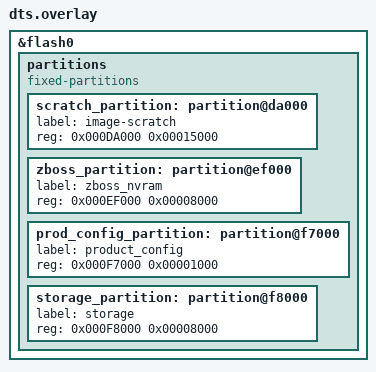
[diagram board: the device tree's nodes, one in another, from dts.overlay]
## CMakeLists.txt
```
#
# Copyright (c) 2020 Nordic Semiconductor ASA
#
# SPDX-License-Identifier: LicenseRef-BSD-5-Clause-Nordic
#

cmake_minimum_required(VERSION 3.13.1)

find_package(Zephyr REQUIRED HINTS $ENV{ZEPHYR_BASE})

project("Zigbee light bulb")

# NORDIC SDK APP START
target_sources(app PRIVATE
  src/main.c
  src/thran.c
)
# NORDIC SDK APP END
```

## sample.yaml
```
sample:
  name: Zigbee Light control
  description: Zigbee Light control - light bulb sample
tests:
  samples.zigbee.light_bulb:
    platform_whitelist: nrf52840dk_nrf52840
    harness: zigbee
    tags: zigbee
  zigbee.light_bulb:
    build_only: true
    build_on_all: true
    platform_whitelist: nrf52840dk_nrf52840 nrf52833dk_nrf52833
    tags: ci_build
```

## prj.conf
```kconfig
#
# Copyright (c) 2020 Nordic Semiconductor ASA
#
# SPDX-License-Identifier: LicenseRef-Nordic-5-Clause
#

CONFIG_NCS_SAMPLES_DEFAULTS=y

CONFIG_UART_INTERRUPT_DRIVEN=y
CONFIG_SERIAL=y
CONFIG_GPIO=y
CONFIG_PWM=y

# Make sure printk is not printing to the UART console
CONFIG_CONSOLE=y
CONFIG_UART_CONSOLE=y

CONFIG_LOG=y

CONFIG_HEAP_MEM_POOL_SIZE=2048
CONFIG_MAIN_THREAD_PRIORITY=7

CONFIG_ZIGBEE=y
CONFIG_ZIGBEE_APP_UTILS=y
CONFIG_ZIGBEE_ROLE_ROUTER=y

# Enable DK LED and Buttons library
CONFIG_DK_LIBRARY=y

# This example requires more workqueue stack
CONFIG_SYSTEM_WORKQUEUE_STACK_SIZE=2048

# Enable nRF ECB driver
CONFIG_CRYPTO=y
CONFIG_CRYPTO_NRF_ECB=y

# Cryptocell is not supported through CSPRNG driver API: NCSDK-4813
CONFIG_ENTROPY_CC3XX=n

#Networking
CONFIG_NET_IPV6_MLD=n
CONFIG_NET_IPV6_NBR_CACHE=n
CONFIG_NET_IPV6_RA_RDNSS=n
CONFIG_NET_IP_ADDR_CHECK=n
CONFIG_NET_UDP=n

#settings storage
CONFIG_NVS=y
CONFIG_SETTINGS=y

#development version of ZBOSS lib
CONFIG_ZIGBEE_LIBRARY_DEVELOPMENT=y
```

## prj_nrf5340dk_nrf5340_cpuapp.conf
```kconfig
#
# Copyright (c) 2020 Nordic Semiconductor ASA
#
# SPDX-License-Identifier: LicenseRef-Nordic-5-Clause
#

CONFIG_NCS_SAMPLES_DEFAULTS=y

CONFIG_UART_INTERRUPT_DRIVEN=y
CONFIG_SERIAL=y
CONFIG_GPIO=y
CONFIG_PWM=y

# Make sure printk is not printing to the UART console
CONFIG_CONSOLE=y
CONFIG_UART_CONSOLE=y

CONFIG_LOG=y

CONFIG_HEAP_MEM_POOL_SIZE=2048
CONFIG_MAIN_THREAD_PRIORITY=7
CONFIG_MAIN_STACK_SIZE=2048

CONFIG_ZIGBEE=y
CONFIG_ZIGBEE_APP_UTILS=y
CONFIG_ZIGBEE_ROLE_ROUTER=y

# Enable DK LED and Buttons library
CONFIG_DK_LIBRARY=y

# This example requires more workqueue stack
CONFIG_SYSTEM_WORKQUEUE_STACK_SIZE=2048

# Use software cryptography on nRF5340
CONFIG_TINYCRYPT=y
CONFIG_CTR_DRBG_CSPRNG_GENERATOR=y
CONFIG_ZIGBEE_USE_SOFTWARE_AES=y

#Networking
CONFIG_MPSL=n
CONFIG_NET_IPV6_MLD=n
CONFIG_NET_IPV6_NBR_CACHE=n
CONFIG_NET_IPV6_RA_RDNSS=n
CONFIG_NET_IP_ADDR_CHECK=n
CONFIG_NET_UDP=n

#settings storage
CONFIG_NVS=y
CONFIG_SETTINGS=y

#development version of ZBOSS lib
CONFIG_ZIGBEE_LIBRARY_DEVELOPMENT=y
```

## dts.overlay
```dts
/* Copyright (c) 2019 Nordic Semiconductor ASA
 *
 * SPDX-License-Identifier: Apache-2.0
 */
 
 /delete-node/ &scratch_partition;
 /delete-node/ &storage_partition;
 
 &flash0 {
	partitions {
		compatible = "fixed-partitions";
		#address-cells = <1>;
		#size-cells = <1>;

		scratch_partition: partition@da000 {
			label = "image-scratch";
			reg = <0x000DA000 0x00015000>;
		};
		zboss_partition: partition@ef000 {
			label = "zboss_nvram";
			reg = <0x000EF000 0x00008000>;
		};
		prod_config_partition: partition@f7000 {
			label = "product_config";
			reg = <0x000F7000 0x00001000>;
		};
		storage_partition: partition@f8000 {
			label = "storage";
			reg = <0x000F8000 0x00008000>;
		};
	};
};
```

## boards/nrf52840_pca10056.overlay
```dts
/* Copyright (c) 2019 Nordic Semiconductor ASA
 *
 * SPDX-License-Identifier: Apache-2.0
 */

/ {
    pwmleds {
		pwm_led3: pwm_led_3 {
			pwms = <&pwm0 16>;
		};
	};
};

&pwm0 {
	ch1-pin = <16>;
	ch1-inverted;
};
```

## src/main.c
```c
/*
 * Copyright (c) 2020 Nordic Semiconductor ASA
 *
 * SPDX-License-Identifier: LicenseRef-Nordic-5-Clause
 */

/** @file
 *
 * @brief Simple Zigbee light bulb implementation.
 */

#include <zephyr/types.h>
#include <zephyr.h>
#include <device.h>
#include <soc.h>
#include <drivers/pwm.h>
#include <logging/log.h>
#include <dk_buttons_and_leds.h>
#include <settings/settings.h>

#include <zboss_api.h>
#include <zboss_api_addons.h>
#include <zb_mem_config_med.h>
#include <zigbee/zigbee_app_utils.h>
#include <zigbee/zigbee_error_handler.h>
#include <zb_nrf_platform.h>

#include "zcl_scenes.h"

#define RUN_STATUS_LED                  DK_LED1
#define RUN_LED_BLINK_INTERVAL          1000

/* Device endpoint, used to receive light controlling commands. */
#define HA_DIMMABLE_LIGHT_ENDPOINT      10

/* Version of the application software (1 byte). */
#define BULB_INIT_BASIC_APP_VERSION     01

/* Version of the implementation of the Zigbee stack (1 byte). */
#define BULB_INIT_BASIC_STACK_VERSION   10

/* Version of the hardware of the device (1 byte). */
#define BULB_INIT_BASIC_HW_VERSION      11

/* Manufacturer name (32 bytes). */
#define BULB_INIT_BASIC_MANUF_NAME      "Nordic"

/* Model number assigned by manufacturer (32-bytes long string). */
#define BULB_INIT_BASIC_MODEL_ID        "Dimable_Light_v0.1"

/* First 8 bytes specify the date of manufacturer of the device
 * in ISO 8601 format (YYYYMMDD). The rest (8 bytes) are manufacturer specific.
 */
#define BULB_INIT_BASIC_DATE_CODE       "20200329"

/* Type of power sources available for the device.
 * For possible values see section 3.2.2.2.8 of ZCL specification.
 */
#define BULB_INIT_BASIC_POWER_SOURCE    ZB_ZCL_BASIC_POWER_SOURCE_DC_SOURCE

/* Describes the physical location of the device (16 bytes).
 * May be modified during commisioning process.
 */
#define BULB_INIT_BASIC_LOCATION_DESC   "Office desk"

/* Describes the type of physical environment.
 * For possible values see section 3.2.2.2.10 of ZCL specification.
 */
#define BULB_INIT_BASIC_PH_ENV          ZB_ZCL_BASIC_ENV_UNSPECIFIED

/* LED indicating that light switch successfully joind Zigbee network. */
#define ZIGBEE_NETWORK_STATE_LED        DK_LED3

/* LED immitaing dimmable light bulb - define for informational
 * purposes only.
 */
#define BULB_LED                        DK_LED4

/* Button used to enter the Bulb into the Identify mode. */
#define IDENTIFY_MODE_BUTTON            DK_BTN4_MSK

/* Use onboard led4 to act as a light bulb.
 * The app.overlay file has this at node label "pwm_led3" in /pwmleds.
 */
#define PWM_DK_LED4_NODE                DT_NODELABEL(pwm_led3)

/* Nordic PWM nodes don't have flags cells in their specifiers, so
 * this is just future-proofing.
 */
#define FLAGS_OR_ZERO(node) \
	COND_CODE_1(DT_PHA_HAS_CELL(node, pwms, flags), \
		    (DT_PWMS_FLAGS(node)), (0))

#if DT_NODE_HAS_STATUS(PWM_DK_LED4_NODE, okay)
/* Get the defines from overlay file. */
#define PWM_DK_LED4_DRIVER              DT_PWMS_LABEL(PWM_DK_LED4_NODE)
#define PWM_DK_LED4_CHANNEL             DT_PWMS_CHANNEL(PWM_DK_LED4_NODE)
#define PWM_DK_LED4_FLAGS               FLAGS_OR_ZERO(PWM_DK_LED4_NODE)
#else
#error "Choose supported PWM driver"
#endif

/* Led PWM period, calculated for 50 Hz signal - in microseconds. */
#define LED_PWM_PERIOD_US               (USEC_PER_SEC / 50U)

#ifndef ZB_ROUTER_ROLE
#error Define ZB_ROUTER_ROLE to compile router source code.
#endif

LOG_MODULE_REGISTER(app);

/* Main application customizable context.
 * Stores all settings and static values.
 */
typedef struct {
	zb_zcl_basic_attrs_ext_t         basic_attr;
	zb_zcl_identify_attrs_t          identify_attr;
	zb_zcl_scenes_attrs_t            scenes_attr;
	zb_zcl_groups_attrs_t            groups_attr;
	zb_zcl_on_off_attrs_t            on_off_attr;
	zb_zcl_level_control_attrs_t     level_control_attr;
} bulb_device_ctx_t;

/* Zigbee device application context storage. */
static bulb_device_ctx_t dev_ctx;

/* Pointer to PWM device controlling leds with pwm signal. */
static const struct device *led_pwm_dev;

ZB_ZCL_DECLARE_IDENTIFY_ATTRIB_LIST(
	identify_attr_list,
	&dev_ctx.identify_attr.identify_time);

ZB_ZCL_DECLARE_GROUPS_ATTRIB_LIST(
	groups_attr_list,
	&dev_ctx.groups_attr.name_support);

ZB_ZCL_DECLARE_SCENES_ATTRIB_LIST(
	scenes_attr_list,
	&dev_ctx.scenes_attr.scene_count,
	&dev_ctx.scenes_attr.current_scene,
	&dev_ctx.scenes_attr.current_group,
	&dev_ctx.scenes_attr.scene_valid,
	&dev_ctx.scenes_attr.name_support);

ZB_ZCL_DECLARE_BASIC_ATTRIB_LIST_EXT(
	basic_attr_list,
	&dev_ctx.basic_attr.zcl_version,
	&dev_ctx.basic_attr.app_version,
	&dev_ctx.basic_attr.stack_version,
	&dev_ctx.basic_attr.hw_version,
	dev_ctx.basic_attr.mf_name,
	dev_ctx.basic_attr.model_id,
	dev_ctx.basic_attr.date_code,
	&dev_ctx.basic_attr.power_source,
	dev_ctx.basic_attr.location_id,
	&dev_ctx.basic_attr.ph_env,
	dev_ctx.basic_attr.sw_ver);

/* On/Off cluster attributes additions data */
ZB_ZCL_DECLARE_ON_OFF_ATTRIB_LIST(
	on_off_attr_list,
	&dev_ctx.on_off_attr.on_off);

ZB_ZCL_DECLARE_LEVEL_CONTROL_ATTRIB_LIST(
	level_control_attr_list,
	&dev_ctx.level_control_attr.current_level,
	&dev_ctx.level_control_attr.remaining_time);

ZB_HA_DECLARE_DIMMABLE_LIGHT_CLUSTER_LIST(
	dimmable_light_clusters,
	basic_attr_list,
	identify_attr_list,
	groups_attr_list,
	scenes_attr_list,
	on_off_attr_list,
	level_control_attr_list);


ZB_HA_DECLARE_DIMMABLE_LIGHT_EP(
	dimmable_light_ep,
	HA_DIMMABLE_LIGHT_ENDPOINT,
	dimmable_light_clusters);

ZB_HA_DECLARE_DIMMABLE_LIGHT_CTX(
	dimmable_light_ctx,
	dimmable_light_ep);

/**@brief Callback for button events.
 *
 * @param[in]   button_state  Bitmask containing buttons state.
 * @param[in]   has_changed   Bitmask containing buttons
 *                            that have changed their state.
 */
static void button_changed(uint32_t button_state, uint32_t has_changed)
{
	zb_ret_t zb_err_code;

	/* Calculate bitmask of buttons that are pressed
	 * and have changed their state.
	 */
	uint32_t buttons = button_state & has_changed;

	if (buttons & IDENTIFY_MODE_BUTTON) {
		/* Check if endpoint is in identifying mode,
		 * if not put desired endpoint in identifying mode.
		 */
		if (dev_ctx.identify_attr.identify_time ==
		    ZB_ZCL_IDENTIFY_IDENTIFY_TIME_DEFAULT_VALUE) {
			LOG_INF("Bulb put in identifying mode");
			zb_err_code = zb_bdb_finding_binding_target(
				HA_DIMMABLE_LIGHT_ENDPOINT);
			ZB_ERROR_CHECK(zb_err_code);
		} else {
			LOG_INF("Cancel F&B target procedure");
			zb_bdb_finding_binding_target_cancel();
		}
	}
}

/**@brief Function for initializing additional PWM leds. */
static void pwm_led_init(void)
{
	led_pwm_dev = device_get_binding(PWM_DK_LED4_DRIVER);

	if (!led_pwm_dev) {
		LOG_ERR("Cannot find %s!", PWM_DK_LED4_DRIVER);
	}
}

/**@brief Function for initializing LEDs and Buttons. */
static void configure_gpio(void)
{
	int err;

	err = dk_buttons_init(button_changed);
	if (err) {
		LOG_ERR("Cannot init buttons (err: %d)", err);
	}

	err = dk_leds_init();
	if (err) {
		LOG_ERR("Cannot init LEDs (err: %d)", err);
	}

	pwm_led_init();
}

/**@brief Sets brightness of bulb luminous executive element
 *
 * @param[in] brightness_level Brightness level, allowed values 0 ... 255,
 *                             0 - turn off, 255 - full brightness.
 */
static void light_bulb_set_brightness(zb_uint8_t brightness_level)
{
	uint32_t pulse = brightness_level * LED_PWM_PERIOD_US / 255U;

	if (pwm_pin_set_usec(led_pwm_dev, PWM_DK_LED4_CHANNEL,
			     LED_PWM_PERIOD_US, pulse, PWM_DK_LED4_FLAGS)) {
		LOG_ERR("Pwm led 4 set fails:\n");
		return;
	}
}

/**@brief Function for setting the light bulb brightness.
 *
 * @param[in] new_level   Light bulb brightness value.
 */
static void level_control_set_value(zb_uint16_t new_level)
{
	LOG_INF("Set level value: %i", new_level);

	ZB_ZCL_SET_ATTRIBUTE(
		HA_DIMMABLE_LIGHT_ENDPOINT,
		ZB_ZCL_CLUSTER_ID_LEVEL_CONTROL,
		ZB_ZCL_CLUSTER_SERVER_ROLE,
		ZB_ZCL_ATTR_LEVEL_CONTROL_CURRENT_LEVEL_ID,
		(zb_uint8_t *)&new_level,
		ZB_FALSE);

	/* According to the table 7.3 of Home Automation Profile Specification
	 * v 1.2 rev 29, chapter 7.1.3.
	 */
	if (new_level == 0) {
		zb_uint8_t value = ZB_FALSE;

		ZB_ZCL_SET_ATTRIBUTE(
			HA_DIMMABLE_LIGHT_ENDPOINT,
			ZB_ZCL_CLUSTER_ID_ON_OFF,
			ZB_ZCL_CLUSTER_SERVER_ROLE,
			ZB_ZCL_ATTR_ON_OFF_ON_OFF_ID,
			&value,
			ZB_FALSE);
	} else {
		zb_uint8_t value = ZB_TRUE;

		ZB_ZCL_SET_ATTRIBUTE(
			HA_DIMMABLE_LIGHT_ENDPOINT,
			ZB_ZCL_CLUSTER_ID_ON_OFF,
			ZB_ZCL_CLUSTER_SERVER_ROLE,
			ZB_ZCL_ATTR_ON_OFF_ON_OFF_ID,
			&value,
			ZB_FALSE);
	}

	light_bulb_set_brightness(new_level);
}

/**@brief Function for turning ON/OFF the light bulb.
 *
 * @param[in]   on   Boolean light bulb state.
 */
static void on_off_set_value(zb_bool_t on)
{
	LOG_INF("Set ON/OFF value: %i", on);

	ZB_ZCL_SET_ATTRIBUTE(
		HA_DIMMABLE_LIGHT_ENDPOINT,
		ZB_ZCL_CLUSTER_ID_ON_OFF,
		ZB_ZCL_CLUSTER_SERVER_ROLE,
		ZB_ZCL_ATTR_ON_OFF_ON_OFF_ID,
		(zb_uint8_t *)&on,
		ZB_FALSE);

	if (on) {
		level_control_set_value(
			dev_ctx.level_control_attr.current_level);
	} else {
		light_bulb_set_brightness(0U);
	}
}

/**@brief Function for initializing all clusters attributes.
 */
static void bulb_clusters_attr_init(void)
{
	/* Basic cluster attributes data */
	dev_ctx.basic_attr.zcl_version   = ZB_ZCL_VERSION;
	dev_ctx.basic_attr.app_version   = BULB_INIT_BASIC_APP_VERSION;
	dev_ctx.basic_attr.stack_version = BULB_INIT_BASIC_STACK_VERSION;
	dev_ctx.basic_attr.hw_version    = BULB_INIT_BASIC_HW_VERSION;

	/* Use ZB_ZCL_SET_STRING_VAL to set strings, because the first byte
	 * should contain string length without trailing zero.
	 *
	 * For example "test" string wil be encoded as:
	 *   [(0x4), 't', 'e', 's', 't']
	 */
	ZB_ZCL_SET_STRING_VAL(
		dev_ctx.basic_attr.mf_name,
		BULB_INIT_BASIC_MANUF_NAME,
		ZB_ZCL_STRING_CONST_SIZE(BULB_INIT_BASIC_MANUF_NAME));

	ZB_ZCL_SET_STRING_VAL(
		dev_ctx.basic_attr.model_id,
		BULB_INIT_BASIC_MODEL_ID,
		ZB_ZCL_STRING_CONST_SIZE(BULB_INIT_BASIC_MODEL_ID));

	ZB_ZCL_SET_STRING_VAL(
		dev_ctx.basic_attr.date_code,
		BULB_INIT_BASIC_DATE_CODE,
		ZB_ZCL_STRING_CONST_SIZE(BULB_INIT_BASIC_DATE_CODE));

	dev_ctx.basic_attr.power_source = BULB_INIT_BASIC_POWER_SOURCE;

	ZB_ZCL_SET_STRING_VAL(
		dev_ctx.basic_attr.location_id,
		BULB_INIT_BASIC_LOCATION_DESC,
		ZB_ZCL_STRING_CONST_SIZE(BULB_INIT_BASIC_LOCATION_DESC));

	dev_ctx.basic_attr.ph_env = BULB_INIT_BASIC_PH_ENV;

	/* Identify cluster attributes data. */
	dev_ctx.identify_attr.identify_time =
		ZB_ZCL_IDENTIFY_IDENTIFY_TIME_DEFAULT_VALUE;

	/* On/Off cluster attributes data. */
	dev_ctx.on_off_attr.on_off = (zb_bool_t)ZB_ZCL_ON_OFF_IS_ON;

	dev_ctx.level_control_attr.current_level =
		ZB_ZCL_LEVEL_CONTROL_LEVEL_MAX_VALUE;
	dev_ctx.level_control_attr.remaining_time =
		ZB_ZCL_LEVEL_CONTROL_REMAINING_TIME_DEFAULT_VALUE;

	ZB_ZCL_SET_ATTRIBUTE(
		HA_DIMMABLE_LIGHT_ENDPOINT,
		ZB_ZCL_CLUSTER_ID_ON_OFF,
		ZB_ZCL_CLUSTER_SERVER_ROLE,
		ZB_ZCL_ATTR_ON_OFF_ON_OFF_ID,
		(zb_uint8_t *)&dev_ctx.on_off_attr.on_off,
		ZB_FALSE);

	ZB_ZCL_SET_ATTRIBUTE(
		HA_DIMMABLE_LIGHT_ENDPOINT,
		ZB_ZCL_CLUSTER_ID_LEVEL_CONTROL,
		ZB_ZCL_CLUSTER_SERVER_ROLE,
		ZB_ZCL_ATTR_LEVEL_CONTROL_CURRENT_LEVEL_ID,
		(zb_uint8_t *)&dev_ctx.level_control_attr.current_level,
		ZB_FALSE);
}

/**@brief Callback function for handling ZCL commands.
 *
 * @param[in]   bufid   Reference to Zigbee stack buffer
 *                      used to pass received data.
 */
static void zcl_device_cb(zb_bufid_t bufid)
{
	zb_uint8_t cluster_id;
	zb_uint8_t attr_id;
	zb_zcl_device_callback_param_t  *device_cb_param =
		ZB_BUF_GET_PARAM(bufid,
				 zb_zcl_device_callback_param_t);
        zb_zcl_device_callback_param_t * p_device_cb_param = ZB_BUF_GET_PARAM(bufid, zb_zcl_device_callback_param_t);


	LOG_INF("%s id %hd", __func__, device_cb_param->device_cb_id);

	/* Set default response value. */
	device_cb_param->status = RET_OK;

	switch (device_cb_param->device_cb_id) {
	case ZB_ZCL_LEVEL_CONTROL_SET_VALUE_CB_ID:
		LOG_INF("Level control setting to %d",
			device_cb_param->cb_param.level_control_set_value_param
				.new_value);
		level_control_set_value(
			device_cb_param->cb_param.level_control_set_value_param
				.new_value);
		break;

	case ZB_ZCL_SET_ATTR_VALUE_CB_ID:
		cluster_id = device_cb_param->cb_param.
			     set_attr_value_param.cluster_id;
		attr_id = device_cb_param->cb_param.
			  set_attr_value_param.attr_id;

		if (cluster_id == ZB_ZCL_CLUSTER_ID_ON_OFF) {
			uint8_t value =
				device_cb_param->cb_param.set_attr_value_param
				.values.data8;

			LOG_INF("on/off attribute setting to %hd", value);
			if (attr_id == ZB_ZCL_ATTR_ON_OFF_ON_OFF_ID) {
				on_off_set_value((zb_bool_t)value);
			}
		} else if (cluster_id == ZB_ZCL_CLUSTER_ID_LEVEL_CONTROL) {
			uint16_t value = device_cb_param->cb_param.
				      set_attr_value_param.values.data16;

			LOG_INF("level control attribute setting to %hd",
				value);
			if (attr_id ==
			    ZB_ZCL_ATTR_LEVEL_CONTROL_CURRENT_LEVEL_ID) {
				level_control_set_value(value);
			}
		} else {
			/* Other clusters can be processed here */
			LOG_INF("Unhandled cluster attribute id: %d",
				cluster_id);
		}
		break;

	default:
		device_cb_param->status = RET_ERROR;

                if (zcl_scenes_cb(bufid) == ZB_TRUE)
                    {
                     /* The frame was handled by the scenes cluster implementation. */
                     p_device_cb_param->status = RET_OK;
                    }

		break;
	}

	LOG_INF("%s status: %hd", __func__, device_cb_param->status);
}

/**@brief Zigbee stack event handler.
 *
 * @param[in]   bufid   Reference to the Zigbee stack buffer
 *                      used to pass signal.
 */
void zboss_signal_handler(zb_bufid_t bufid)
{
	/* Update network status LED. */
	zigbee_led_status_update(bufid, ZIGBEE_NETWORK_STATE_LED);

	/* No application-specific behavior is required.
	 * Call default signal handler.
	 */
	ZB_ERROR_CHECK(zigbee_default_signal_handler(bufid));

	/* All callbacks should either reuse or free passed buffers.
	 * If bufid == 0, the buffer is invalid (not passed).
	 */
	if (bufid) {
		zb_buf_free(bufid);
	}
}

void error(void)
{
	dk_set_leds_state(DK_ALL_LEDS_MSK, DK_NO_LEDS_MSK);

	while (true) {
		/* Spin forever */
		k_sleep(K_MSEC(1000));
	}
}

void main(void)
{
	int blink_status = 0;

	LOG_INF("Starting ZBOSS Light Bulb example");

	/* Initialize */
	configure_gpio();
	settings_subsys_init();

	/* Register callback for handling ZCL commands. */
	ZB_ZCL_REGISTER_DEVICE_CB(zcl_device_cb);

	/* Register dimmer switch device context (endpoints). */
	ZB_AF_REGISTER_DEVICE_CTX(&dimmable_light_ctx);

	bulb_clusters_attr_init();
	level_control_set_value(dev_ctx.level_control_attr.current_level);

        /** Initialize ZCL scene table */
        zcl_scenes_init();

	/* Settings should be loaded after zcl_scenes_init */
	settings_load();

	/* Start Zigbee default thread */
	zigbee_enable();

	LOG_INF("ZBOSS Light Bulb example started");

	while (1) {
		dk_set_led(RUN_STATUS_LED, (++blink_status) % 2);
		k_sleep(K_MSEC(RUN_LED_BLINK_INTERVAL));
	}
}
```

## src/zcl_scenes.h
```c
/**
 * Copyright (c) 2020, Nordic Semiconductor ASA
 *
 * All rights reserved.
 *
 * Redistribution and use in source and binary forms, with or without modification,
 * are permitted provided that the following conditions are met:
 *
 * 1. Redistributions of source code must retain the above copyright notice, this
 *    list of conditions and the following disclaimer.
 *
 * 2. Redistributions in binary form, except as embedded into a Nordic
 *    Semiconductor ASA integrated circuit in a product or a software update for
 *    such product, must reproduce the above copyright notice, this list of
 *    conditions and the following disclaimer in the documentation and/or other
 *    materials provided with the distribution.
 *
 * 3. Neither the name of Nordic Semiconductor ASA nor the names of its
 *    contributors may be used to endorse or promote products derived from this
 *    software without specific prior written permission.
 *
 * 4. This software, with or without modification, must only be used with a
 *    Nordic Semiconductor ASA integrated circuit.
 *
 * 5. Any software provided in binary form under this license must not be reverse
 *    engineered, decompiled, modified and/or disassembled.
 *
 * THIS SOFTWARE IS PROVIDED BY NORDIC SEMICONDUCTOR ASA "AS IS" AND ANY EXPRESS
 * OR IMPLIED WARRANTIES, INCLUDING, BUT NOT LIMITED TO, THE IMPLIED WARRANTIES
 * OF MERCHANTABILITY, NONINFRINGEMENT, AND FITNESS FOR A PARTICULAR PURPOSE ARE
 * DISCLAIMED. IN NO EVENT SHALL NORDIC SEMICONDUCTOR ASA OR CONTRIBUTORS BE
 * LIABLE FOR ANY DIRECT, INDIRECT, INCIDENTAL, SPECIAL, EXEMPLARY, OR
 * CONSEQUENTIAL DAMAGES (INCLUDING, BUT NOT LIMITED TO, PROCUREMENT OF SUBSTITUTE
 * GOODS OR SERVICES; LOSS OF USE, DATA, OR PROFITS; OR BUSINESS INTERRUPTION)
 * HOWEVER CAUSED AND ON ANY THEORY OF LIABILITY, WHETHER IN CONTRACT, STRICT
 * LIABILITY, OR TORT (INCLUDING NEGLIGENCE OR OTHERWISE) ARISING IN ANY WAY OUT
 * OF THE USE OF THIS SOFTWARE, EVEN IF ADVISED OF THE POSSIBILITY OF SUCH DAMAGE.
 *
 */
#ifndef ZCL_SCENES_H__
#define ZCL_SCENES_H__

#include "zboss_api.h"


#define ZCL_SCENES_ENDPOINT   10
#define ZCL_SCENES_TABLE_SIZE 3


/** Initialize ZCL scene table. */
void zcl_scenes_init(void);

/** Handle scene-related ZCL callbacks. */
zb_bool_t zcl_scenes_cb(zb_uint8_t param);

#endif /* ZCL_SCENES_H__ */
```
